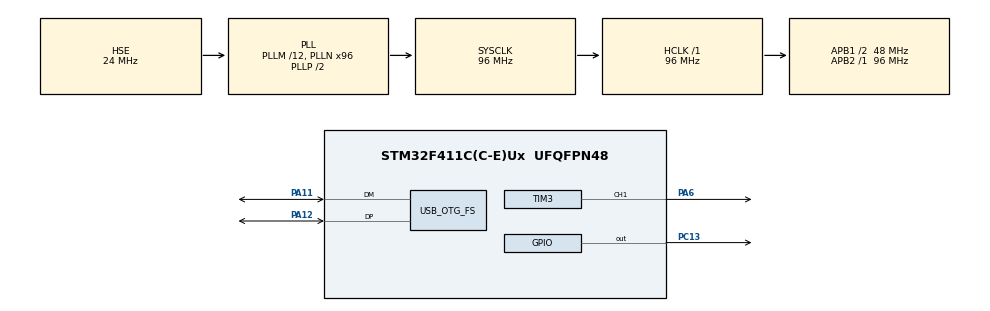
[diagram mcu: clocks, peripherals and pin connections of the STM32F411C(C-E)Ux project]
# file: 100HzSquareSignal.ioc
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Mcu.Family=STM32F4
Mcu.Name=STM32F411C(C-E)Ux
Mcu.Package=UFQFPN48
NVIC.OTG_FS_IRQn=true\:0\:0\:false\:false\:true\:false\:true\:true
NVIC.PriorityGroup=NVIC_PRIORITYGROUP_4
PA11.Mode=Device_Only
PA11.Signal=USB_OTG_FS_DM
PA12.Mode=Device_Only
PA12.Signal=USB_OTG_FS_DP
PA13.Mode=Serial_Wire
PA13.Signal=SYS_JTMS-SWDIO
PA14.Mode=Serial_Wire
PA14.Signal=SYS_JTCK-SWCLK
PA6.Signal=S_TIM3_CH1
PC13-ANTI_TAMP.GPIO_PuPd=GPIO_PULLUP
PC13-ANTI_TAMP.Signal=GPIO_Output
PH0\ -\ OSC_IN.Mode=HSE-External-Oscillator
PH0\ -\ OSC_IN.Signal=RCC_OSC_IN
PH1\ -\ OSC_OUT.Mode=HSE-External-Oscillator
PH1\ -\ OSC_OUT.Signal=RCC_OSC_OUT
ProjectManager.HeapSize=0x200
ProjectManager.StackSize=0x400
ProjectManager.TargetToolchain=STM32CubeIDE
RCC.48MHZClocksFreq_Value=48000000
RCC.AHBFreq_Value=96000000
RCC.APB1CLKDivider=RCC_HCLK_DIV2
RCC.APB1Freq_Value=48000000
RCC.APB1TimFreq_Value=96000000
RCC.APB2Freq_Value=96000000
RCC.APB2TimFreq_Value=96000000
RCC.CortexFreq_Value=96000000
RCC.HCLKFreq_Value=96000000
RCC.HSE_VALUE=24000000
RCC.HSI_VALUE=16000000
RCC.LSE_VALUE=32768
RCC.PLLM=12
RCC.PLLN=96
RCC.SYSCLKFreq_VALUE=96000000
RCC.SYSCLKSource=RCC_SYSCLKSOURCE_PLLCLK
RCC.VCOOutputFreq_Value=192000000
SH.S_TIM3_CH1.0=TIM3_CH1,PWM Generation1 CH1
TIM3.Channel-PWM\ Generation1\ CH1=TIM_CHANNEL_1
TIM3.OCPolarity_1=TIM_OCPOLARITY_LOW
TIM3.Period=10000-1
TIM3.Prescaler=96-1
TIM3.Pulse-PWM\ Generation1\ CH1=5000-1
USB_DEVICE.CLASS_NAME_FS=CDC
USB_DEVICE.VirtualMode=Cdc
USB_DEVICE.VirtualModeFS=Cdc_FS
USB_OTG_FS.VirtualMode=Device_Only
VP_TIM3_VS_ClockSourceINT.Mode=Internal
VP_USB_DEVICE_VS_USB_DEVICE_CDC_FS.Mode=CDC_FS
board=custom

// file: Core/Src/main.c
/* USER CODE BEGIN Header */
/**
 ******************************************************************************
 * @file           : main.c
 * @brief          : Main program body
 ******************************************************************************
 * @attention
 *
 * Copyright (c) 2024 STMicroelectronics.
 * All rights reserved.
 *
 * This software is licensed under terms that can be found in the LICENSE file
 * in the root directory of this software component.
 * If no LICENSE file comes with this software, it is provided AS-IS.
 *
 ******************************************************************************
 */
/* USER CODE END Header */
#include "main.h"
#include "usb_device.h"

TIM_HandleTypeDef htim3;

/* USER CODE BEGIN PV */
HAL_StatusTypeDef Ret;
GPIO_PinState pinState;
char buffer[32];
/* USER CODE END PV */

void SystemClock_Config(void);
static void MX_GPIO_Init(void);
static void MX_TIM3_Init(void);
/* USER CODE BEGIN PFP */
extern uint8_t CDC_Transmit_FS(uint8_t *Buf, uint16_t Len);
/* USER CODE END PFP */

int main(void) {

	/* MCU Configuration--------------------------------------------------------*/

	/* Reset of all peripherals, Initializes the Flash interface and the Systick. */
	HAL_Init();

	/* Configure the system clock */
	SystemClock_Config();

	/* Initialize all configured peripherals */
	MX_GPIO_Init();
	MX_TIM3_Init();
	MX_USB_DEVICE_Init();
	/* USER CODE BEGIN 2 */
	Ret = HAL_TIM_PWM_Start(&htim3, TIM_CHANNEL_1);
	if (Ret == HAL_OK) {
		HAL_GPIO_WritePin(GPIOC, GPIO_PIN_13, GPIO_PIN_RESET);
	}
	/* USER CODE END 2 */

	/* Infinite loop */
	/* USER CODE BEGIN WHILE */
	while (1) {
		pinState = HAL_GPIO_ReadPin(GPIOA, GPIO_PIN_6);
		sprintf(buffer, "%d\n", pinState);
		CDC_Transmit_FS((uint8_t*) buffer, strlen(buffer));

		/* USER CODE END WHILE */

	}
}

void SystemClock_Config(void) {
	RCC_OscInitTypeDef RCC_OscInitStruct = { 0 };
	RCC_ClkInitTypeDef RCC_ClkInitStruct = { 0 };

	/** Configure the main internal regulator output voltage
	 */
	__HAL_RCC_PWR_CLK_ENABLE();
	__HAL_PWR_VOLTAGESCALING_CONFIG(PWR_REGULATOR_VOLTAGE_SCALE1);

	/** Initializes the RCC Oscillators according to the specified parameters
	 * in the RCC_OscInitTypeDef structure.
	 */
	RCC_OscInitStruct.OscillatorType = RCC_OSCILLATORTYPE_HSE;
	RCC_OscInitStruct.HSEState = RCC_HSE_ON;
	RCC_OscInitStruct.PLL.PLLState = RCC_PLL_ON;
	RCC_OscInitStruct.PLL.PLLSource = RCC_PLLSOURCE_HSE;
	RCC_OscInitStruct.PLL.PLLM = 12;
	RCC_OscInitStruct.PLL.PLLN = 96;
	RCC_OscInitStruct.PLL.PLLP = RCC_PLLP_DIV2;
	RCC_OscInitStruct.PLL.PLLQ = 4;
	if (HAL_RCC_OscConfig(&RCC_OscInitStruct) != HAL_OK) {
		Error_Handler();
	}

	/** Initializes the CPU, AHB and APB buses clocks
	 */
	RCC_ClkInitStruct.ClockType = RCC_CLOCKTYPE_HCLK | RCC_CLOCKTYPE_SYSCLK
			| RCC_CLOCKTYPE_PCLK1 | RCC_CLOCKTYPE_PCLK2;
	RCC_ClkInitStruct.SYSCLKSource = RCC_SYSCLKSOURCE_PLLCLK;
	RCC_ClkInitStruct.AHBCLKDivider = RCC_SYSCLK_DIV1;
	RCC_ClkInitStruct.APB1CLKDivider = RCC_HCLK_DIV2;
	RCC_ClkInitStruct.APB2CLKDivider = RCC_HCLK_DIV1;

	if (HAL_RCC_ClockConfig(&RCC_ClkInitStruct, FLASH_LATENCY_3) != HAL_OK) {
		Error_Handler();
	}
}

static void MX_TIM3_Init(void) {

	TIM_ClockConfigTypeDef sClockSourceConfig = { 0 };
	TIM_MasterConfigTypeDef sMasterConfig = { 0 };
	TIM_OC_InitTypeDef sConfigOC = { 0 };

	htim3.Instance = TIM3;
	htim3.Init.Prescaler = 96 - 1;
	htim3.Init.CounterMode = TIM_COUNTERMODE_UP;
	htim3.Init.Period = 10000 - 1;
	htim3.Init.ClockDivision = TIM_CLOCKDIVISION_DIV1;
	htim3.Init.AutoReloadPreload = TIM_AUTORELOAD_PRELOAD_DISABLE;
	if (HAL_TIM_Base_Init(&htim3) != HAL_OK) {
		Error_Handler();
	}
	sClockSourceConfig.ClockSource = TIM_CLOCKSOURCE_INTERNAL;
	if (HAL_TIM_ConfigClockSource(&htim3, &sClockSourceConfig) != HAL_OK) {
		Error_Handler();
	}
	if (HAL_TIM_PWM_Init(&htim3) != HAL_OK) {
		Error_Handler();
	}
	sMasterConfig.MasterOutputTrigger = TIM_TRGO_RESET;
	sMasterConfig.MasterSlaveMode = TIM_MASTERSLAVEMODE_DISABLE;
	if (HAL_TIMEx_MasterConfigSynchronization(&htim3, &sMasterConfig)
			!= HAL_OK) {
		Error_Handler();
	}
	sConfigOC.OCMode = TIM_OCMODE_PWM1;
	sConfigOC.Pulse = 5000 - 1;
	sConfigOC.OCPolarity = TIM_OCPOLARITY_LOW;
	sConfigOC.OCFastMode = TIM_OCFAST_DISABLE;
	if (HAL_TIM_PWM_ConfigChannel(&htim3, &sConfigOC, TIM_CHANNEL_1)
			!= HAL_OK) {
		Error_Handler();
	}
	HAL_TIM_MspPostInit(&htim3);

}

static void MX_GPIO_Init(void) {
	GPIO_InitTypeDef GPIO_InitStruct = { 0 };

	/* GPIO Ports Clock Enable */
	__HAL_RCC_GPIOC_CLK_ENABLE();
	__HAL_RCC_GPIOH_CLK_ENABLE();
	__HAL_RCC_GPIOA_CLK_ENABLE();

	/*Configure GPIO pin Output Level */
	HAL_GPIO_WritePin(GPIOC, GPIO_PIN_13, GPIO_PIN_RESET);

	/*Configure GPIO pin : PC13 */
	GPIO_InitStruct.Pin = GPIO_PIN_13;
	GPIO_InitStruct.Mode = GPIO_MODE_OUTPUT_PP;
	GPIO_InitStruct.Pull = GPIO_PULLUP;
	GPIO_InitStruct.Speed = GPIO_SPEED_FREQ_LOW;
	HAL_GPIO_Init(GPIOC, &GPIO_InitStruct);

}

void Error_Handler(void) {
	__disable_irq();
	while (1) {
	}
}
